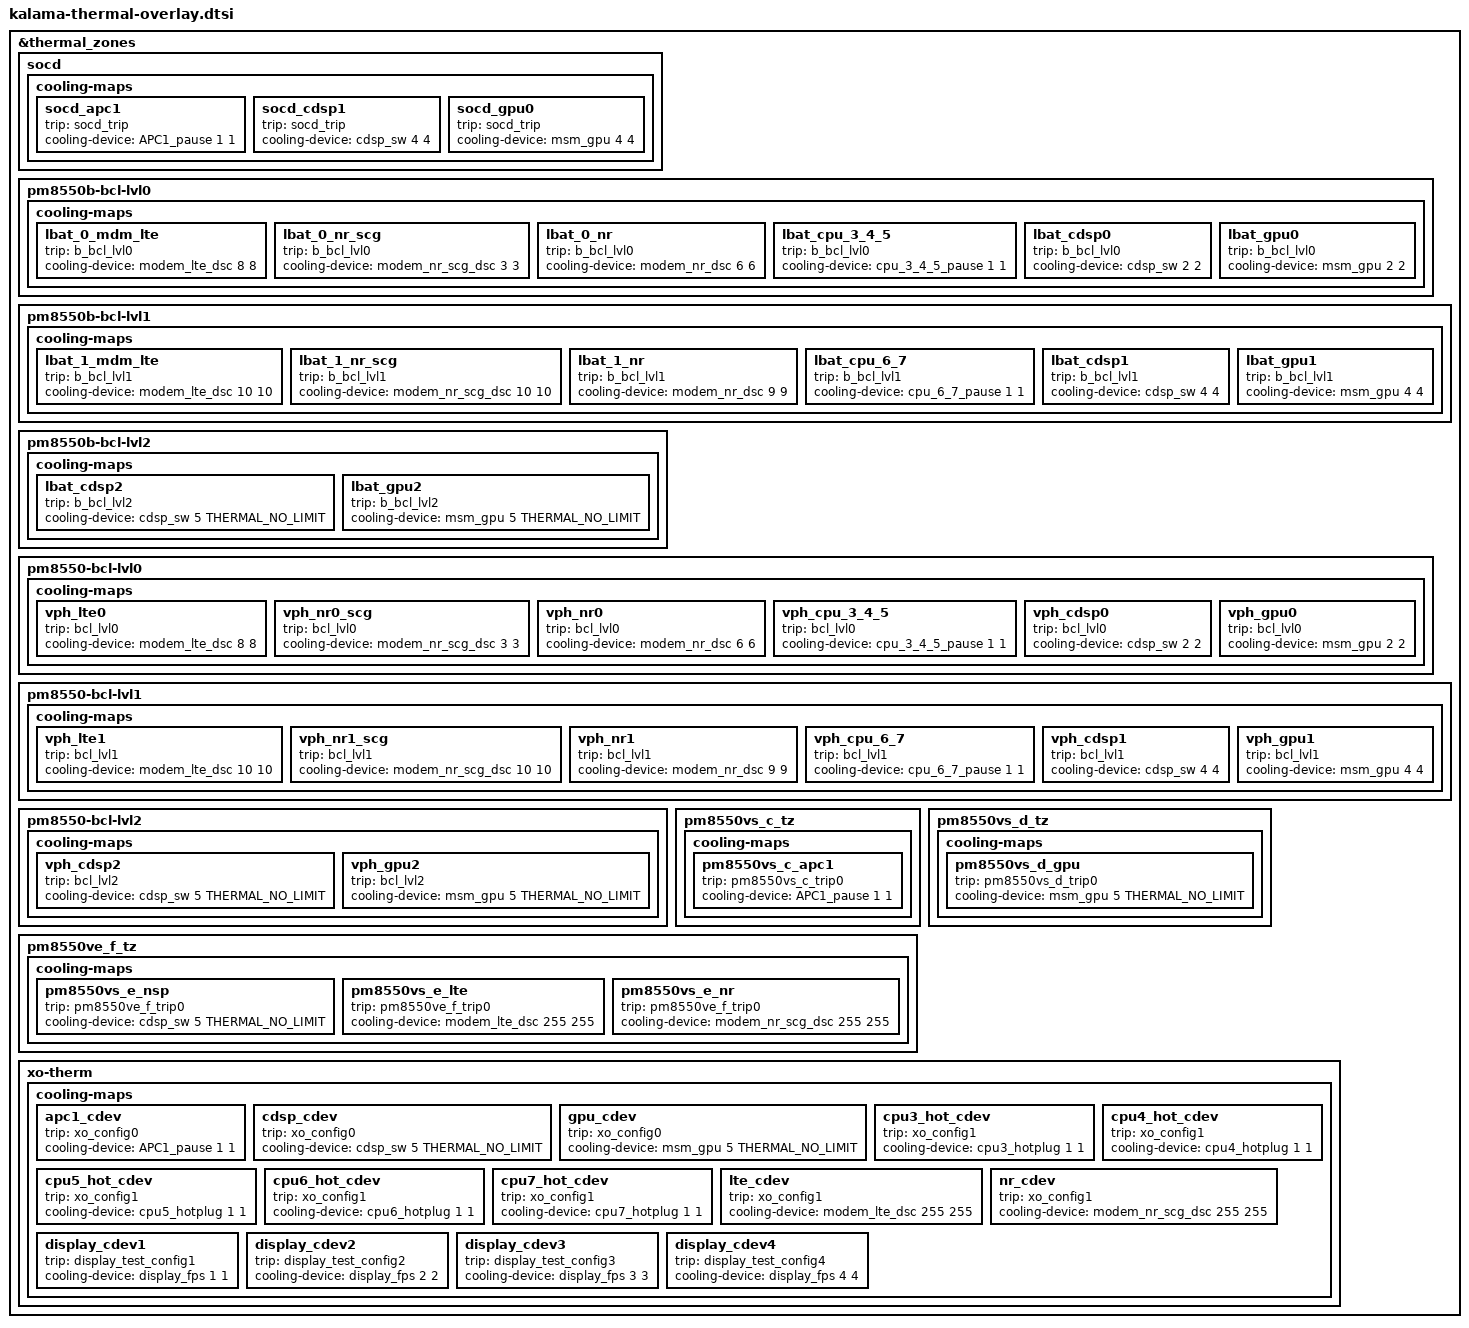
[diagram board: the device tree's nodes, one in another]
#include <dt-bindings/thermal/thermal_qti.h>

&thermal_zones {
	socd {
		cooling-maps {
			socd_apc1 {
				trip = <&socd_trip>;
				cooling-device = <&APC1_pause 1 1>;
			};

			socd_cdsp1 {
				trip = <&socd_trip>;
				cooling-device = <&cdsp_sw 4 4>;
			};

			socd_gpu0 {
				trip = <&socd_trip>;
				cooling-device = <&msm_gpu 4 4>;
			};
		};
	};

	pm8550b-bcl-lvl0 {
		cooling-maps {
			lbat_0_mdm_lte {
				trip = <&b_bcl_lvl0>;
				cooling-device = <&modem_lte_dsc 8 8>;
			};

			lbat_0_nr_scg {
				trip = <&b_bcl_lvl0>;
				cooling-device = <&modem_nr_scg_dsc 3 3>;
			};

			lbat_0_nr {
				trip = <&b_bcl_lvl0>;
				cooling-device = <&modem_nr_dsc 6 6>;
			};

			lbat_cpu_3_4_5 {
				trip = <&b_bcl_lvl0>;
				cooling-device = <&cpu_3_4_5_pause 1 1>;
			};

			lbat_cdsp0 {
				trip = <&b_bcl_lvl0>;
				cooling-device = <&cdsp_sw 2 2>;
			};

			lbat_gpu0 {
				trip = <&b_bcl_lvl0>;
				cooling-device = <&msm_gpu 2 2>;
			};
		};
	};

	pm8550b-bcl-lvl1 {
		cooling-maps {
			lbat_1_mdm_lte {
				trip = <&b_bcl_lvl1>;
				cooling-device = <&modem_lte_dsc 10 10>;
			};

			lbat_1_nr_scg {
				trip = <&b_bcl_lvl1>;
				cooling-device = <&modem_nr_scg_dsc 10 10>;
			};

			lbat_1_nr {
				trip = <&b_bcl_lvl1>;
				cooling-device = <&modem_nr_dsc 9 9>;
			};

			lbat_cpu_6_7 {
				trip = <&b_bcl_lvl1>;
				cooling-device = <&cpu_6_7_pause 1 1>;
			};

			lbat_cdsp1 {
				trip = <&b_bcl_lvl1>;
				cooling-device = <&cdsp_sw 4 4>;
			};

			lbat_gpu1 {
				trip = <&b_bcl_lvl1>;
				cooling-device = <&msm_gpu 4 4>;
			};
		};
	};

	pm8550b-bcl-lvl2 {
		cooling-maps {
			lbat_cdsp2 {
				trip = <&b_bcl_lvl2>;
				cooling-device = <&cdsp_sw 5 THERMAL_NO_LIMIT>;
			};

			lbat_gpu2 {
				trip = <&b_bcl_lvl2>;
				cooling-device = <&msm_gpu 5 THERMAL_NO_LIMIT>;
			};
		};
	};

	pm8550-bcl-lvl0 {
		cooling-maps {
			vph_lte0 {
				trip = <&bcl_lvl0>;
				cooling-device = <&modem_lte_dsc 8 8>;
			};

			vph_nr0_scg {
				trip = <&bcl_lvl0>;
				cooling-device = <&modem_nr_scg_dsc 3 3>;
			};

			vph_nr0 {
				trip = <&bcl_lvl0>;
				cooling-device = <&modem_nr_dsc 6 6>;
			};

			vph_cpu_3_4_5 {
				trip = <&bcl_lvl0>;
				cooling-device = <&cpu_3_4_5_pause 1 1>;
			};

			vph_cdsp0 {
				trip = <&bcl_lvl0>;
				cooling-device = <&cdsp_sw 2 2>;
			};

			vph_gpu0 {
				trip = <&bcl_lvl0>;
				cooling-device = <&msm_gpu 2 2>;
			};
		};
	};

	pm8550-bcl-lvl1 {
		cooling-maps {
			vph_lte1 {
				trip = <&bcl_lvl1>;
				cooling-device = <&modem_lte_dsc 10 10>;
			};

			vph_nr1_scg {
				trip = <&bcl_lvl1>;
				cooling-device = <&modem_nr_scg_dsc 10 10>;
			};

			vph_nr1 {
				trip = <&bcl_lvl1>;
				cooling-device = <&modem_nr_dsc 9 9>;
			};

			vph_cpu_6_7 {
				trip = <&bcl_lvl1>;
				cooling-device = <&cpu_6_7_pause 1 1>;
			};

			vph_cdsp1 {
				trip = <&bcl_lvl1>;
				cooling-device = <&cdsp_sw 4 4>;
			};

			vph_gpu1 {
				trip = <&bcl_lvl1>;
				cooling-device = <&msm_gpu 4 4>;
			};
		};
	};

	pm8550-bcl-lvl2 {
		cooling-maps {
			vph_cdsp2 {
				trip = <&bcl_lvl2>;
				cooling-device = <&cdsp_sw 5 THERMAL_NO_LIMIT>;
			};

			vph_gpu2 {
				trip = <&bcl_lvl2>;
				cooling-device = <&msm_gpu 5 THERMAL_NO_LIMIT>;
			};
		};
	};

	pm8550vs_c_tz {
		cooling-maps {
			pm8550vs_c_apc1 {
				trip = <&pm8550vs_c_trip0>;
				cooling-device = <&APC1_pause 1 1>;
			};
		};
	};

	pm8550vs_d_tz {
		cooling-maps {
			pm8550vs_d_gpu {
				trip = <&pm8550vs_d_trip0>;
				cooling-device = <&msm_gpu 5 THERMAL_NO_LIMIT>;
			};
		};
	};

	pm8550ve_f_tz {
		cooling-maps {
			pm8550vs_e_nsp {
				trip = <&pm8550ve_f_trip0>;
				cooling-device = <&cdsp_sw 5 THERMAL_NO_LIMIT>;
			};

			pm8550vs_e_lte {
				trip = <&pm8550ve_f_trip0>;
				cooling-device = <&modem_lte_dsc 255 255>;
			};

			pm8550vs_e_nr {
				trip = <&pm8550ve_f_trip0>;
				cooling-device = <&modem_nr_scg_dsc 255 255>;
			};
		};
	};

	xo-therm {
		cooling-maps {
			apc1_cdev {
				trip = <&xo_config0>;
				cooling-device = <&APC1_pause 1 1>;
			};

			cdsp_cdev {
				trip = <&xo_config0>;
				cooling-device = <&cdsp_sw 5 THERMAL_NO_LIMIT>;
			};

			gpu_cdev {
				trip = <&xo_config0>;
				cooling-device = <&msm_gpu 5 THERMAL_NO_LIMIT>;
			};

			cpu3_hot_cdev {
				trip = <&xo_config1>;
				cooling-device = <&cpu3_hotplug 1 1>;
			};

			cpu4_hot_cdev {
				trip = <&xo_config1>;
				cooling-device = <&cpu4_hotplug 1 1>;
			};

			cpu5_hot_cdev {
				trip = <&xo_config1>;
				cooling-device = <&cpu5_hotplug 1 1>;
			};

			cpu6_hot_cdev {
				trip = <&xo_config1>;
				cooling-device = <&cpu6_hotplug 1 1>;
			};

			cpu7_hot_cdev {
				trip = <&xo_config1>;
				cooling-device = <&cpu7_hotplug 1 1>;
			};

			lte_cdev {
				trip = <&xo_config1>;
				cooling-device = <&modem_lte_dsc 255 255>;
			};

			nr_cdev {
				trip = <&xo_config1>;
				cooling-device = <&modem_nr_scg_dsc 255 255>;
			};

			display_cdev1 {
				trip = <&display_test_config1>;
				cooling-device = <&display_fps 1 1>;
			};

			display_cdev2 {
				trip = <&display_test_config2>;
				cooling-device = <&display_fps 2 2>;
			};

			display_cdev3 {
				trip = <&display_test_config3>;
				cooling-device = <&display_fps 3 3>;
			};

			display_cdev4 {
				trip = <&display_test_config4>;
				cooling-device = <&display_fps 4 4>;
			};
		};
	};
};
